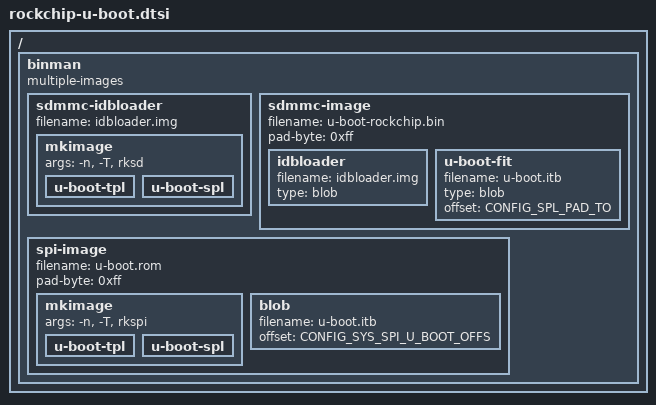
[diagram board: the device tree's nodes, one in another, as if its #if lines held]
// SPDX-License-Identifier: GPL-2.0+
/*
 * Copyright (C) 2019 Jagan Teki <jagan@amarulasolutions.com>
 */

#include <config.h>

/ {
	binman: binman {
		multiple-images;
	};
};

#ifdef CONFIG_SPL
&binman {
	sdmmc-idbloader {
		filename = "idbloader.img";

		mkimage {
			args = "-n", CONFIG_SYS_SOC, "-T", "rksd";

#ifdef CONFIG_TPL
			u-boot-tpl {
			};
#endif
			u-boot-spl {
			};
		};
	};

	sdmmc-image {
		filename = "u-boot-rockchip.bin";
		pad-byte = <0xff>;

		idbloader {
			filename = "idbloader.img";
			type = "blob";
		};

#if defined(CONFIG_SPL_FIT) && defined(CONFIG_ARM64)
		u-boot-fit {
			filename = "u-boot.itb";
			type = "blob";
			offset = <CONFIG_SPL_PAD_TO>;
		};
#else
		u-boot-img {
		};
#endif
	};
};

#ifdef CONFIG_ROCKCHIP_SPI_IMAGE
&binman {
	spi-image {
		filename = "u-boot.rom";
		pad-byte = <0xff>;

		mkimage {
			args = "-n", CONFIG_SYS_SOC, "-T", "rkspi";

#ifdef CONFIG_TPL
			u-boot-tpl {
			};
#endif
			u-boot-spl {
			};
		};

#if defined(CONFIG_SPL_FIT) && defined(CONFIG_ARM64)
		blob {
			filename = "u-boot.itb";
			offset = <CONFIG_SYS_SPI_U_BOOT_OFFS>;
		};
#else
		u-boot-img {
		};
#endif
	};
};
#endif // CONFIG_ROCKCHIP_SPI_IMAGE
#endif // CONFIG_SPL
